AUTOSAR XML (schema 4-3-0)
standard types defined: uint8, uint16, uint32, float32, boolean
package /DataTypes
  4 x impl type:
    VehicleSpeed_T: category=VALUE, base-type=float32, range raw 0..300, unit=km/h
    EngineRPM_T: category=VALUE, base-type=uint16, range raw 0..10000, unit=rpm
    TemperatureValue_T: category=VALUE, base-type=float32, range raw -50..150, unit=°C
    EngineState_T: category=TYPE_REFERENCE, compu {0=OFF, 1=RUNNING, 2=CRANKING, 3=STALLING}, base-type=uint8
package /Units
  unit KilometersPerHour: display-name=km/h, factor-si-to-unit=3.6, offset-si-to-unit=0
  unit RevolutionsPerMinute: display-name=rpm, factor-si-to-unit=60, offset-si-to-unit=0
  unit Celsius: display-name=°C, factor-si-to-unit=1, offset-si-to-unit=-273.15
package /Interfaces
  sender receiver interface VehicleSpeed_I
    data Speed: type=VehicleSpeed_T
  sender receiver interface EngineStatus_I
    data RPM: type=EngineRPM_T
    data State: type=EngineState_T
    data Temperature: type=TemperatureValue_T
  client server interface EngineControl_I
    operation Start: possible-error=[E_BUSY, E_NOT_OK]
      arg StartType: type=EngineState_T, direction=IN
    operation Stop: possible-error=E_NOT_OK
    error E_BUSY: error-code=1
    error E_NOT_OK: error-code=2
package /ComponentTypes
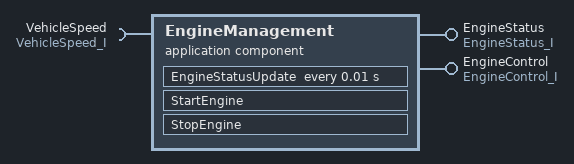
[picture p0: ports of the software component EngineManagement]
  application software component type EngineManagement
    provide port EngineStatus: provided-interface=EngineStatus_I
    require port VehicleSpeed: required-interface=VehicleSpeed_I
    provide port EngineControl: provided-interface=EngineControl_I
    behavior EngineManagement_Behavior
      timing event Engine_10ms_Event: start-on-event=EngineStatusUpdate, period=0.01
      operation invoked event EngineStart_Event: start-on-event=StartEngine, operation=EngineControl.Start
      operation invoked event EngineStop_Event: start-on-event=StopEngine, operation=EngineControl.Stop
      runnable EngineStatusUpdate
        data-write-access:
          access Write_RPM: accessed-variable=EngineStatus.RPM
          access Write_State: accessed-variable=EngineStatus.State
          access Write_Temperature: accessed-variable=EngineStatus.Temperature
        data-read-access:
          access Read_VehicleSpeed: accessed-variable=VehicleSpeed.Speed
      runnable StartEngine
        data-write-access:
          access Write_State: accessed-variable=EngineStatus.State
      runnable StopEngine
        data-write-access:
          access Write_State: accessed-variable=EngineStatus.State
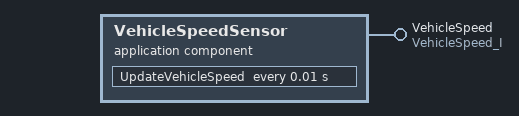
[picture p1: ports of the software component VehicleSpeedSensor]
  application software component type VehicleSpeedSensor
    provide port VehicleSpeed: provided-interface=VehicleSpeed_I
    behavior VehicleSpeedSensor_Behavior
      timing event SpeedUpdate_10ms_Event: start-on-event=UpdateVehicleSpeed, period=0.01
      runnable UpdateVehicleSpeed
        data-write-access:
          access Write_Speed: accessed-variable=VehicleSpeed.Speed
package /CompositionTypes
  composition sw component type VehiclePowertrainComposition
    component EngineManagement_Prototype: type=EngineManagement
    component VehicleSpeedSensor_Prototype: type=VehicleSpeedSensor
    connect VehicleSpeedSensor_Prototype.VehicleSpeed -> EngineManagement_Prototype.VehicleSpeed
package /Parameters
  parameter sw component type EngineParameters
    parameter data prototype IdleRPM: type=EngineRPM_T, value=800
    parameter data prototype MaxRPM: type=EngineRPM_T, value=6500
    parameter data prototype OperatingTemp: type=TemperatureValue_T, value=90.0
  parameter sw component type VehicleParameters
    parameter data prototype MaxSpeed: type=VehicleSpeed_T, value=220.0
